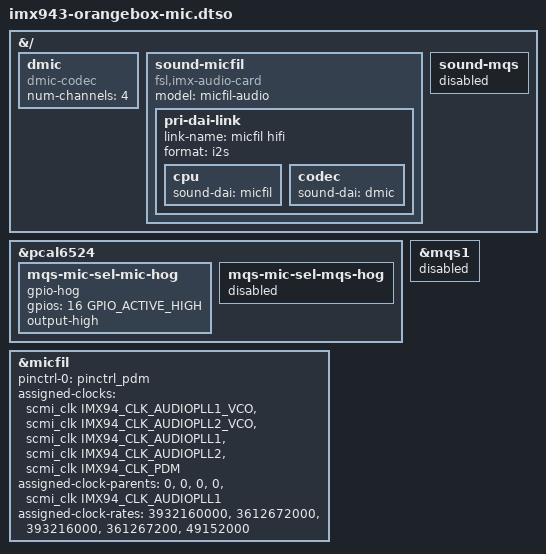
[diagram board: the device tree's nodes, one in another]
// SPDX-License-Identifier: (GPL-2.0+ OR MIT)
/*
 * Copyright 2025 NXP
 */

#include <dt-bindings/gpio/gpio.h>
#include "imx94-clock.h"

/dts-v1/;
/plugin/;

&{/} {
	dmic: dmic {
		compatible = "dmic-codec";
		#sound-dai-cells = <0>;
		num-channels = <4>;
	};

	sound-micfil {
		compatible = "fsl,imx-audio-card";
		model = "micfil-audio";

		pri-dai-link {
			link-name = "micfil hifi";
			format = "i2s";

			cpu {
				sound-dai = <&micfil>;
			};

			codec {
				sound-dai = <&dmic>;
			};
		};
	};

	sound-mqs {
		status = "disabled";
	};
};

&pcal6524 {
	mqs-mic-sel-mic-hog {
		gpio-hog;
		gpios = <16 GPIO_ACTIVE_HIGH>;
		output-high;
	};

	mqs-mic-sel-mqs-hog {
		status = "disabled";
	};
};

&micfil {
	pinctrl-names = "default";
	pinctrl-0 = <&pinctrl_pdm>;
	assigned-clocks = <&scmi_clk IMX94_CLK_AUDIOPLL1_VCO>,
			  <&scmi_clk IMX94_CLK_AUDIOPLL2_VCO>,
			  <&scmi_clk IMX94_CLK_AUDIOPLL1>,
			  <&scmi_clk IMX94_CLK_AUDIOPLL2>,
			  <&scmi_clk IMX94_CLK_PDM>;
	assigned-clock-parents = <0>, <0>, <0>, <0>,
				 <&scmi_clk IMX94_CLK_AUDIOPLL1>;
	assigned-clock-rates = <3932160000>,
			       <3612672000>, <393216000>,
			       <361267200>, <49152000>;
	status = "okay";
};

&mqs1 {
	status = "disabled";
};
